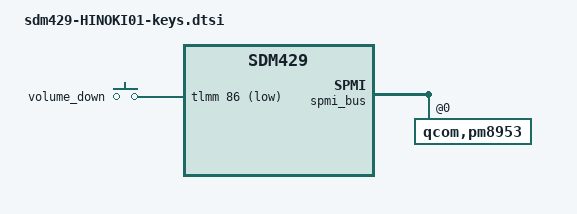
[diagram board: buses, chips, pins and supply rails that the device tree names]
/*
 * This software is contributed or developed by KYOCERA Corporation.
 * (C) 2019 KYOCERA Corporation
 *
 * This program is free software; you can redistribute it and/or modify
 * it under the terms of the GNU General Public License version 2 and
 * only version 2 as published by the Free Software Foundation.
 *
 * This program is distributed in the hope that it will be useful,
 * but WITHOUT ANY WARRANTY; without even the implied warranty of
 * MERCHANTABILITY or FITNESS FOR A PARTICULAR PURPOSE.  See the
 * GNU General Public License for more details.
 */

&spmi_bus {
	qcom,pm8953@0 {
		qcom,power-on@800 {
			qcom,pon_2 {
				linux,code = <115>;
			};
		};
	};
};

&soc {
	/delete-node/ gpio_keys;

	gpio_keys {
		compatible = "gpio-keys";
		label = "gpio-keys";

		vol_down {
			label = "volume_down";
			gpios = <&tlmm 86 0x1>;
			linux,input-type = <1>;
			linux,code = <114>;
			debounce-interval = <15>;
			linux,can-disable;
			gpio-key,wakeup;
		};
	};

	/delete-node/ tlmm_gpio_key;

};

